# NAVSS0_PVU_1_ALIAS64K_IO_PVU1_CFG_TLBIF_TLB register map
Vendor: Texas Instruments
Peripheral module from a debugger description file (folder J721S2).
Registers are 32-bit, read-write, reset 0x0 unless marked. A register's access mark holds for its fields unless they carry their own. Offsets are as the file gives them; lines under a group give offsets from that group; [hi:lo] are bit positions; {n}, {i} and the like mark numbered series; 'fields as' and 'values as' point back to an identical list; <NAME> marks a mode.

## NAVSS0_PVU_1_ALIAS64K_IO_PVU1_CFG_TLBIF_TLB
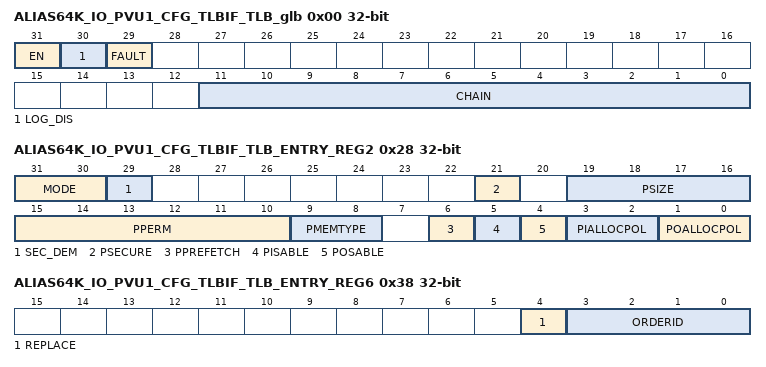
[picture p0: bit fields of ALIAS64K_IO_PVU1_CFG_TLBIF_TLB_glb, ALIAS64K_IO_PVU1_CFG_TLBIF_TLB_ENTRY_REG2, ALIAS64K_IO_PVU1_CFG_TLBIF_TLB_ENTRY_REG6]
0x00 ALIAS64K_IO_PVU1_CFG_TLBIF_TLB_glb — The TLB chain points to another TLB. The a is the TLB number, and the b is the entry number within a TLB.
  [31] EN — Enable for the TLB. 0 = disable TLB. 1 = enable TLB.
  [30] LOG_DIS — Disable Fault Logging for the TLB. 0 = enable fault logging. 1 = disable fault logging.
  [29] FAULT — A fault has been detected from this TLB that could not be logged. Will be set by hardware, and can be cleared by software.
  [11:0] CHAIN — Chain to another TLB. 0 = no chain. 1+ = chain to that TLB number.
0x20 ALIAS64K_IO_PVU1_CFG_TLBIF_TLB_ENTRY_REG0 — The TLB Entry. The a is the TLB number, and the b is the entry number within a TLB. The address must be aligned to the page size.
  [31:0] VBASE_L — Virtual Base Address bits 31 to 0. The address must be aligned to the page size.
0x24 ALIAS64K_IO_PVU1_CFG_TLBIF_TLB_ENTRY_REG1 — The TLB Entry. The a is the TLB number, and the b is the entry number within a TLB. The address must be aligned to the page size.
  [15:0] VBASE_H — Virtual Base Address bits 47 to 32. The address must be aligned to the page size.
0x28 ALIAS64K_IO_PVU1_CFG_TLBIF_TLB_ENTRY_REG2 — The TLB Entry. The a is the TLB number, and the b is the entry number within a TLB.
  [31:30] MODE — Entry mode. 0 = invalid. 1 = reserved - do not use. 2 = valid. 3 = reserved - do not use.
  [29] SEC_DEM — Enable Secure Transaction Demotion for the entry if the PVU is in secure mode. 0 = Secure Transactions are not affected. 1 = Secure Transactions that match the entry is demoted to non-secure out of the PVU.
  [21] PSECURE — LPAE Field for Secure Page
  [19:16] PSIZE — LPAE Field for Page Size. 0 = 4K. 1 = 16K. 2 = 64K. 3 = 2M. 4 = 32M. 5 = 512M. 6 = 1G. 7 = 16G.
  [15:10] PPERM — LPAE Field for Page Permissions. Bit0 = enable user read access UR. Bit1 = enable user write access UW. Bit2 = enable user execute access UX. Bit3 = enable supervisor read access SR. Bit4 = enable supervisor write access SW. Bit5 = enable supervisor execute access SX.
  [9:8] PMEMTYPE — LPAE Field for Page Memory Type. 0 = device. 1 = write back. 2 = write through.
  [6] PPREFETCH — LPAE Field for Page Prefetch allowed
  [5] PISABLE — LPAE Field for Page Inner Shareable allowed
  [4] POSABLE — LPAE Field for Page Outer Shareable allowed
  [3:2] PIALLOCPOL — LPAE Field for Page Inner Allocation Policy. 0 = no allocate. 1 = write allocate. 2 = read allocate. 3 = read and write allocate.
  [1:0] POALLOCPOL — LPAE Field for Page Outer Allocation Policy. 0 = no allocate. 1 = write allocate. 2 = read allocate. 3 = read and write allocate.
0x30 ALIAS64K_IO_PVU1_CFG_TLBIF_TLB_ENTRY_REG4 — The TLB Entry. The a is the TLB number, and the b is the entry number within a TLB. The address must be aligned to the page size.
  [31:0] PBASE_L — Physical Base Address bits 31 to 0. The address must be aligned to the page size.
0x34 ALIAS64K_IO_PVU1_CFG_TLBIF_TLB_ENTRY_REG5 — The TLB Entry. The a is the TLB number, and the b is the entry number within a TLB. The address must be aligned to the page size.
  [15:0] PBASE_H — Physical Base Address bits 47 to 32. The address must be aligned to the page size.
0x38 ALIAS64K_IO_PVU1_CFG_TLBIF_TLB_ENTRY_REG6 ro — The TLB Entry. The a is the TLB number, and the b is the entry number within a TLB.
  [4] REPLACE — Indicates to replace the bus orderid value when matching this entry with the orderid MMR field. This allows control over the orderid value when it must be restricted due to the topology for QoS reasons. 0 = bypass and use the orderid from the source transaction for the destination transaction. 1 = use the orderid MMR field value for the destination transaction.
  [3:0] ORDERID — Defines the bus orderid value for this entry if hit.
